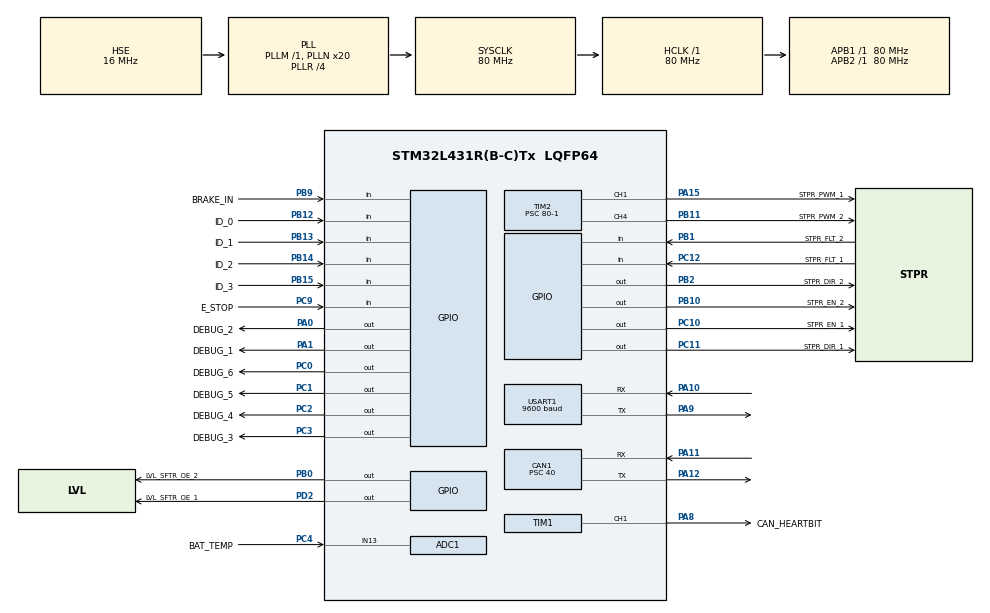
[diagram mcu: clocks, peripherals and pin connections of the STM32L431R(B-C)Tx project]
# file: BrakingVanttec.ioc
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ADC1.Channel-6\#ChannelRegularConversion=ADC_CHANNEL_TEMPSENSOR
ADC1.ContinuousConvMode=ENABLE
ADC1.NbrOfConversionFlag=1
ADC1.OffsetNumber-6\#ChannelRegularConversion=ADC_OFFSET_NONE
ADC1.Rank-6\#ChannelRegularConversion=1
ADC1.SamplingTime-6\#ChannelRegularConversion=ADC_SAMPLETIME_2CYCLES_5
ADC1.master=1
CAN1.BS1=CAN_BS1_13TQ
CAN1.BS2=CAN_BS2_2TQ
CAN1.CalculateBaudRate=125000
CAN1.CalculateTimeBit=8000
CAN1.CalculateTimeQuantum=500.0
CAN1.Prescaler=40
FREERTOS.Tasks01=defaultTask,32,128,default_task,Default,NULL,Dynamic,NULL,NULL
FREERTOS.configGENERATE_RUN_TIME_STATS=1
FREERTOS.configRECORD_STACK_HIGH_ADDRESS=1
FREERTOS.configTIMER_TASK_PRIORITY=6
FREERTOS.configTOTAL_HEAP_SIZE=20000
FREERTOS.configUSE_NEWLIB_REENTRANT=1
FREERTOS.configUSE_STATS_FORMATTING_FUNCTIONS=1
Mcu.Family=STM32L4
Mcu.Name=STM32L431R(B-C)Tx
Mcu.Package=LQFP64
NVIC.PriorityGroup=NVIC_PRIORITYGROUP_4
NVIC.TIM6_DAC_IRQn=true\:15\:0\:false\:false\:true\:false\:false\:true\:true
NVIC.TimeBase=TIM6_DAC_IRQn
NVIC.TimeBaseIP=TIM6
PA0.GPIO_Label=DEBUG_2
PA0.Signal=GPIO_Output
PA1.GPIO_Label=DEBUG_1
PA1.Signal=GPIO_Output
PA10.Mode=Asynchronous
PA10.Signal=USART1_RX
PA11.Mode=CAN_Activate
PA11.Signal=CAN1_RX
PA12.Mode=CAN_Activate
PA12.Signal=CAN1_TX
PA13\ (JTMS-SWDIO).Mode=Trace_Asynchronous_SW
PA13\ (JTMS-SWDIO).Signal=SYS_JTMS-SWDIO
PA14\ (JTCK-SWCLK).Mode=Trace_Asynchronous_SW
PA14\ (JTCK-SWCLK).Signal=SYS_JTCK-SWCLK
PA15\ (JTDI).GPIO_Label=STPR_PWM_1
PA15\ (JTDI).Signal=S_TIM2_CH1
PA8.GPIO_Label=CAN_HEARTBIT
PA8.Signal=S_TIM1_CH1
PA9.Mode=Asynchronous
PA9.Signal=USART1_TX
PB0.GPIO_Label=LVL_SFTR_OE_2
PB0.Signal=GPIO_Output
PB1.GPIO_Label=STPR_FLT_2
PB1.Signal=GPIO_Input
PB10.GPIO_Label=STPR_EN_2
PB10.Signal=GPIO_Output
PB11.GPIO_Label=STPR_PWM_2
PB11.Signal=S_TIM2_CH4
PB12.GPIO_Label=ID_0
PB12.Signal=GPIO_Input
PB13.GPIO_Label=ID_1
PB13.Signal=GPIO_Input
PB14.GPIO_Label=ID_2
PB14.Signal=GPIO_Input
PB15.GPIO_Label=ID_3
PB15.Signal=GPIO_Input
PB2.GPIO_Label=STPR_DIR_2
PB2.Signal=GPIO_Output
PB3\ (JTDO-TRACESWO).Mode=Trace_Asynchronous_SW
PB3\ (JTDO-TRACESWO).Signal=SYS_JTDO-SWO
PB9.GPIO_Label=BRAKE_IN
PB9.Signal=GPIO_Input
PC0.GPIO_Label=DEBUG_6
PC0.Signal=GPIO_Output
PC1.GPIO_Label=DEBUG_5
PC1.Signal=GPIO_Output
PC10.GPIO_Label=STPR_EN_1
PC10.Signal=GPIO_Output
PC11.GPIO_Label=STPR_DIR_1
PC11.Signal=GPIO_Output
PC12.GPIO_Label=STPR_FLT_1
PC12.Signal=GPIO_Input
PC2.GPIO_Label=DEBUG_4
PC2.Signal=GPIO_Output
PC3.GPIO_Label=DEBUG_3
PC3.Signal=GPIO_Output
PC4.GPIO_Label=BAT_TEMP
PC4.Signal=SharedAnalog_PC4
PC9.GPIO_Label=E_STOP
PC9.Signal=GPIO_Input
PD2.GPIO_Label=LVL_SFTR_OE_1
PD2.Signal=GPIO_Output
PH0-OSC_IN\ (PH0).Mode=HSE-External-Oscillator
PH0-OSC_IN\ (PH0).Signal=RCC_OSC_IN
PH1-OSC_OUT\ (PH1).Mode=HSE-External-Oscillator
PH1-OSC_OUT\ (PH1).Signal=RCC_OSC_OUT
ProjectManager.HeapSize=0x200
ProjectManager.StackSize=0x400
ProjectManager.TargetToolchain=STM32CubeIDE
RCC.ADCFreq_Value=80000000
RCC.AHBFreq_Value=80000000
RCC.APB1Freq_Value=80000000
RCC.APB1TimFreq_Value=80000000
RCC.APB2Freq_Value=80000000
RCC.APB2TimFreq_Value=80000000
RCC.CortexFreq_Value=80000000
RCC.HCLKFreq_Value=80000000
RCC.HSE_VALUE=16000000
RCC.HSI48_VALUE=48000000
RCC.HSI_VALUE=16000000
RCC.LSE_VALUE=32768
RCC.MSI_VALUE=4000000
RCC.PLLN=20
RCC.PLLR=RCC_PLLR_DIV4
RCC.PLLSAI1N=20
RCC.PLLSAI1R=RCC_PLLR_DIV4
RCC.PLLSourceVirtual=RCC_PLLSOURCE_HSE
RCC.SYSCLKFreq_VALUE=80000000
RCC.SYSCLKSource=RCC_SYSCLKSOURCE_PLLCLK
RCC.VCOOutputFreq_Value=320000000
SH.S_TIM1_CH1.0=TIM1_CH1,PWM Generation1 CH1
SH.S_TIM2_CH1.0=TIM2_CH1,PWM Generation1 CH1
SH.S_TIM2_CH4.0=TIM2_CH4,PWM Generation4 CH4
SH.SharedAnalog_PC4.0=GPIO_Analog
SH.SharedAnalog_PC4.1=ADC1_IN13,IN13-Single-Ended
TIM1.Channel-PWM\ Generation1\ CH1=TIM_CHANNEL_1
TIM1.Period=100-1
TIM1.Prescaler=80-1
TIM2.Channel-PWM\ Generation1\ CH1=TIM_CHANNEL_1
TIM2.Channel-PWM\ Generation4\ CH4=TIM_CHANNEL_4
TIM2.Period=5000-1 
TIM2.Prescaler=80-1
USART1.BaudRate=9600
USART1.VirtualMode-Asynchronous=VM_ASYNC
VP_ADC1_TempSens_Input.Mode=IN-TempSens
VP_FREERTOS_VS_CMSIS_V2.Mode=CMSIS_V2
VP_SYS_VS_tim6.Mode=TIM6
VP_TIM1_VS_ClockSourceINT.Mode=Internal
VP_TIM2_VS_ClockSourceINT.Mode=Internal
board=custom

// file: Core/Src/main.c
/* USER CODE BEGIN Header */
/**
  ******************************************************************************
  * @file           : main.c
  * @brief          : Main program body
  ******************************************************************************
  * @attention
  *
  * Copyright (c) 2023 STMicroelectronics.
  * All rights reserved.
  *
  * This software is licensed under terms that can be found in the LICENSE file
  * in the root directory of this software component.
  * If no LICENSE file comes with this software, it is provided AS-IS.
  *
  ******************************************************************************
  */
/* USER CODE END Header */
#include "main.h"
#include "cmsis_os.h"

/* USER CODE BEGIN Includes */
#include "stepper_tasks.h"
#include "vanttec_sdv_ids.h"
/* USER CODE END Includes */

ADC_HandleTypeDef hadc1;

CAN_HandleTypeDef hcan1;

TIM_HandleTypeDef htim1;
TIM_HandleTypeDef htim2;

UART_HandleTypeDef huart1;

/* Definitions for defaultTask */
osThreadId_t defaultTaskHandle;
const osThreadAttr_t defaultTask_attributes = {
  .name = "defaultTask",
  .stack_size = 128 * 4,
  .priority = (osPriority_t) osPriorityAboveNormal,
};

void SystemClock_Config(void);
static void MX_GPIO_Init(void);
static void MX_USART1_UART_Init(void);
static void MX_TIM2_Init(void);
static void MX_TIM1_Init(void);
static void MX_ADC1_Init(void);
static void MX_CAN1_Init(void);
void default_task(void *argument);

int main(void)
{

  /* MCU Configuration--------------------------------------------------------*/

  /* Reset of all peripherals, Initializes the Flash interface and the Systick. */
  HAL_Init();

  /* Configure the system clock */
  SystemClock_Config();

  /* Initialize all configured peripherals */
  MX_GPIO_Init();
  MX_USART1_UART_Init();
  MX_TIM2_Init();
  MX_TIM1_Init();
  MX_ADC1_Init();
  MX_CAN1_Init();
  /* USER CODE BEGIN 2 */
  init_canlib(hcan1, VANTTEC_CAN_ID_BRAKING_TX);
  init_canlib_tx();
  init_canlib_rx();
  canlib_init_generic_tasks();
  init_requirements_task();
  init_stepper_tasks();
  /* USER CODE END 2 */

  /* Init scheduler */
  osKernelInitialize();

  /* Create the thread(s) */
  /* creation of defaultTask */
  defaultTaskHandle = osThreadNew(default_task, NULL, &defaultTask_attributes);

  /* Start scheduler */
  osKernelStart();

  /* We should never get here as control is now taken by the scheduler */
  /* Infinite loop */
  while (1)
  {

  }
}

void SystemClock_Config(void)
{
  RCC_OscInitTypeDef RCC_OscInitStruct = {0};
  RCC_ClkInitTypeDef RCC_ClkInitStruct = {0};

  /** Configure the main internal regulator output voltage
  */
  if (HAL_PWREx_ControlVoltageScaling(PWR_REGULATOR_VOLTAGE_SCALE1) != HAL_OK)
  {
    Error_Handler();
  }

  /** Initializes the RCC Oscillators according to the specified parameters
  * in the RCC_OscInitTypeDef structure.
  */
  RCC_OscInitStruct.OscillatorType = RCC_OSCILLATORTYPE_HSE;
  RCC_OscInitStruct.HSEState = RCC_HSE_ON;
  RCC_OscInitStruct.PLL.PLLState = RCC_PLL_ON;
  RCC_OscInitStruct.PLL.PLLSource = RCC_PLLSOURCE_HSE;
  RCC_OscInitStruct.PLL.PLLM = 1;
  RCC_OscInitStruct.PLL.PLLN = 20;
  RCC_OscInitStruct.PLL.PLLP = RCC_PLLP_DIV7;
  RCC_OscInitStruct.PLL.PLLQ = RCC_PLLQ_DIV2;
  RCC_OscInitStruct.PLL.PLLR = RCC_PLLR_DIV4;
  if (HAL_RCC_OscConfig(&RCC_OscInitStruct) != HAL_OK)
  {
    Error_Handler();
  }

  /** Initializes the CPU, AHB and APB buses clocks
  */
  RCC_ClkInitStruct.ClockType = RCC_CLOCKTYPE_HCLK|RCC_CLOCKTYPE_SYSCLK
                              |RCC_CLOCKTYPE_PCLK1|RCC_CLOCKTYPE_PCLK2;
  RCC_ClkInitStruct.SYSCLKSource = RCC_SYSCLKSOURCE_PLLCLK;
  RCC_ClkInitStruct.AHBCLKDivider = RCC_SYSCLK_DIV1;
  RCC_ClkInitStruct.APB1CLKDivider = RCC_HCLK_DIV1;
  RCC_ClkInitStruct.APB2CLKDivider = RCC_HCLK_DIV1;

  if (HAL_RCC_ClockConfig(&RCC_ClkInitStruct, FLASH_LATENCY_4) != HAL_OK)
  {
    Error_Handler();
  }
}

static void MX_ADC1_Init(void)
{

  ADC_ChannelConfTypeDef sConfig = {0};

  /** Common config
  */
  hadc1.Instance = ADC1;
  hadc1.Init.ClockPrescaler = ADC_CLOCK_ASYNC_DIV1;
  hadc1.Init.Resolution = ADC_RESOLUTION_12B;
  hadc1.Init.DataAlign = ADC_DATAALIGN_RIGHT;
  hadc1.Init.ScanConvMode = ADC_SCAN_DISABLE;
  hadc1.Init.EOCSelection = ADC_EOC_SINGLE_CONV;
  hadc1.Init.LowPowerAutoWait = DISABLE;
  hadc1.Init.ContinuousConvMode = ENABLE;
  hadc1.Init.NbrOfConversion = 1;
  hadc1.Init.DiscontinuousConvMode = DISABLE;
  hadc1.Init.ExternalTrigConv = ADC_SOFTWARE_START;
  hadc1.Init.ExternalTrigConvEdge = ADC_EXTERNALTRIGCONVEDGE_NONE;
  hadc1.Init.DMAContinuousRequests = DISABLE;
  hadc1.Init.Overrun = ADC_OVR_DATA_PRESERVED;
  hadc1.Init.OversamplingMode = DISABLE;
  if (HAL_ADC_Init(&hadc1) != HAL_OK)
  {
    Error_Handler();
  }

  /** Configure Regular Channel
  */
  sConfig.Channel = ADC_CHANNEL_TEMPSENSOR;
  sConfig.Rank = ADC_REGULAR_RANK_1;
  sConfig.SamplingTime = ADC_SAMPLETIME_2CYCLES_5;
  sConfig.SingleDiff = ADC_SINGLE_ENDED;
  sConfig.OffsetNumber = ADC_OFFSET_NONE;
  sConfig.Offset = 0;
  if (HAL_ADC_ConfigChannel(&hadc1, &sConfig) != HAL_OK)
  {
    Error_Handler();
  }

}

static void MX_CAN1_Init(void)
{

  hcan1.Instance = CAN1;
  hcan1.Init.Prescaler = 40;
  hcan1.Init.Mode = CAN_MODE_NORMAL;
  hcan1.Init.SyncJumpWidth = CAN_SJW_1TQ;
  hcan1.Init.TimeSeg1 = CAN_BS1_13TQ;
  hcan1.Init.TimeSeg2 = CAN_BS2_2TQ;
  hcan1.Init.TimeTriggeredMode = DISABLE;
  hcan1.Init.AutoBusOff = DISABLE;
  hcan1.Init.AutoWakeUp = DISABLE;
  hcan1.Init.AutoRetransmission = DISABLE;
  hcan1.Init.ReceiveFifoLocked = DISABLE;
  hcan1.Init.TransmitFifoPriority = DISABLE;
  if (HAL_CAN_Init(&hcan1) != HAL_OK)
  {
    Error_Handler();
  }

}

static void MX_TIM1_Init(void)
{

  TIM_ClockConfigTypeDef sClockSourceConfig = {0};
  TIM_MasterConfigTypeDef sMasterConfig = {0};
  TIM_OC_InitTypeDef sConfigOC = {0};
  TIM_BreakDeadTimeConfigTypeDef sBreakDeadTimeConfig = {0};

  htim1.Instance = TIM1;
  htim1.Init.Prescaler = 80-1;
  htim1.Init.CounterMode = TIM_COUNTERMODE_UP;
  htim1.Init.Period = 100-1;
  htim1.Init.ClockDivision = TIM_CLOCKDIVISION_DIV1;
  htim1.Init.RepetitionCounter = 0;
  htim1.Init.AutoReloadPreload = TIM_AUTORELOAD_PRELOAD_DISABLE;
  if (HAL_TIM_Base_Init(&htim1) != HAL_OK)
  {
    Error_Handler();
  }
  sClockSourceConfig.ClockSource = TIM_CLOCKSOURCE_INTERNAL;
  if (HAL_TIM_ConfigClockSource(&htim1, &sClockSourceConfig) != HAL_OK)
  {
    Error_Handler();
  }
  if (HAL_TIM_PWM_Init(&htim1) != HAL_OK)
  {
    Error_Handler();
  }
  sMasterConfig.MasterOutputTrigger = TIM_TRGO_RESET;
  sMasterConfig.MasterOutputTrigger2 = TIM_TRGO2_RESET;
  sMasterConfig.MasterSlaveMode = TIM_MASTERSLAVEMODE_DISABLE;
  if (HAL_TIMEx_MasterConfigSynchronization(&htim1, &sMasterConfig) != HAL_OK)
  {
    Error_Handler();
  }
  sConfigOC.OCMode = TIM_OCMODE_PWM1;
  sConfigOC.Pulse = 0;
  sConfigOC.OCPolarity = TIM_OCPOLARITY_HIGH;
  sConfigOC.OCNPolarity = TIM_OCNPOLARITY_HIGH;
  sConfigOC.OCFastMode = TIM_OCFAST_DISABLE;
  sConfigOC.OCIdleState = TIM_OCIDLESTATE_RESET;
  sConfigOC.OCNIdleState = TIM_OCNIDLESTATE_RESET;
  if (HAL_TIM_PWM_ConfigChannel(&htim1, &sConfigOC, TIM_CHANNEL_1) != HAL_OK)
  {
    Error_Handler();
  }
  sBreakDeadTimeConfig.OffStateRunMode = TIM_OSSR_DISABLE;
  sBreakDeadTimeConfig.OffStateIDLEMode = TIM_OSSI_DISABLE;
  sBreakDeadTimeConfig.LockLevel = TIM_LOCKLEVEL_OFF;
  sBreakDeadTimeConfig.DeadTime = 0;
  sBreakDeadTimeConfig.BreakState = TIM_BREAK_DISABLE;
  sBreakDeadTimeConfig.BreakPolarity = TIM_BREAKPOLARITY_HIGH;
  sBreakDeadTimeConfig.BreakFilter = 0;
  sBreakDeadTimeConfig.Break2State = TIM_BREAK2_DISABLE;
  sBreakDeadTimeConfig.Break2Polarity = TIM_BREAK2POLARITY_HIGH;
  sBreakDeadTimeConfig.Break2Filter = 0;
  sBreakDeadTimeConfig.AutomaticOutput = TIM_AUTOMATICOUTPUT_DISABLE;
  if (HAL_TIMEx_ConfigBreakDeadTime(&htim1, &sBreakDeadTimeConfig) != HAL_OK)
  {
    Error_Handler();
  }
  HAL_TIM_MspPostInit(&htim1);

}

static void MX_TIM2_Init(void)
{

  TIM_ClockConfigTypeDef sClockSourceConfig = {0};
  TIM_MasterConfigTypeDef sMasterConfig = {0};
  TIM_OC_InitTypeDef sConfigOC = {0};

  htim2.Instance = TIM2;
  htim2.Init.Prescaler = 80-1;
  htim2.Init.CounterMode = TIM_COUNTERMODE_UP;
  htim2.Init.Period = 1000-1 ;
  htim2.Init.ClockDivision = TIM_CLOCKDIVISION_DIV1;
  htim2.Init.AutoReloadPreload = TIM_AUTORELOAD_PRELOAD_DISABLE;
  if (HAL_TIM_Base_Init(&htim2) != HAL_OK)
  {
    Error_Handler();
  }
  sClockSourceConfig.ClockSource = TIM_CLOCKSOURCE_INTERNAL;
  if (HAL_TIM_ConfigClockSource(&htim2, &sClockSourceConfig) != HAL_OK)
  {
    Error_Handler();
  }
  if (HAL_TIM_PWM_Init(&htim2) != HAL_OK)
  {
    Error_Handler();
  }
  sMasterConfig.MasterOutputTrigger = TIM_TRGO_RESET;
  sMasterConfig.MasterSlaveMode = TIM_MASTERSLAVEMODE_DISABLE;
  if (HAL_TIMEx_MasterConfigSynchronization(&htim2, &sMasterConfig) != HAL_OK)
  {
    Error_Handler();
  }
  sConfigOC.OCMode = TIM_OCMODE_PWM1;
  sConfigOC.Pulse = 0;
  sConfigOC.OCPolarity = TIM_OCPOLARITY_HIGH;
  sConfigOC.OCFastMode = TIM_OCFAST_DISABLE;
  if (HAL_TIM_PWM_ConfigChannel(&htim2, &sConfigOC, TIM_CHANNEL_1) != HAL_OK)
  {
    Error_Handler();
  }
  if (HAL_TIM_PWM_ConfigChannel(&htim2, &sConfigOC, TIM_CHANNEL_4) != HAL_OK)
  {
    Error_Handler();
  }
  HAL_TIM_MspPostInit(&htim2);

}

static void MX_USART1_UART_Init(void)
{

  huart1.Instance = USART1;
  huart1.Init.BaudRate = 9600;
  huart1.Init.WordLength = UART_WORDLENGTH_8B;
  huart1.Init.StopBits = UART_STOPBITS_1;
  huart1.Init.Parity = UART_PARITY_NONE;
  huart1.Init.Mode = UART_MODE_TX_RX;
  huart1.Init.HwFlowCtl = UART_HWCONTROL_NONE;
  huart1.Init.OverSampling = UART_OVERSAMPLING_16;
  huart1.Init.OneBitSampling = UART_ONE_BIT_SAMPLE_DISABLE;
  huart1.AdvancedInit.AdvFeatureInit = UART_ADVFEATURE_NO_INIT;
  if (HAL_UART_Init(&huart1) != HAL_OK)
  {
    Error_Handler();
  }

}

static void MX_GPIO_Init(void)
{
  GPIO_InitTypeDef GPIO_InitStruct = {0};

  /* GPIO Ports Clock Enable */
  __HAL_RCC_GPIOH_CLK_ENABLE();
  __HAL_RCC_GPIOC_CLK_ENABLE();
  __HAL_RCC_GPIOA_CLK_ENABLE();
  __HAL_RCC_GPIOB_CLK_ENABLE();
  __HAL_RCC_GPIOD_CLK_ENABLE();

  /*Configure GPIO pin Output Level */
  HAL_GPIO_WritePin(GPIOC, DEBUG_6_Pin|DEBUG_5_Pin|DEBUG_4_Pin|DEBUG_3_Pin
                          |STPR_EN_1_Pin|STPR_DIR_1_Pin, GPIO_PIN_RESET);

  /*Configure GPIO pin Output Level */
  HAL_GPIO_WritePin(GPIOA, DEBUG_2_Pin|DEBUG_1_Pin, GPIO_PIN_RESET);

  /*Configure GPIO pin Output Level */
  HAL_GPIO_WritePin(GPIOB, LVL_SFTR_OE_2_Pin|STPR_DIR_2_Pin|STPR_EN_2_Pin, GPIO_PIN_RESET);

  /*Configure GPIO pin Output Level */
  HAL_GPIO_WritePin(LVL_SFTR_OE_1_GPIO_Port, LVL_SFTR_OE_1_Pin, GPIO_PIN_RESET);

  /*Configure GPIO pins : DEBUG_6_Pin DEBUG_5_Pin DEBUG_4_Pin DEBUG_3_Pin
                           STPR_EN_1_Pin STPR_DIR_1_Pin */
  GPIO_InitStruct.Pin = DEBUG_6_Pin|DEBUG_5_Pin|DEBUG_4_Pin|DEBUG_3_Pin
                          |STPR_EN_1_Pin|STPR_DIR_1_Pin;
  GPIO_InitStruct.Mode = GPIO_MODE_OUTPUT_PP;
  GPIO_InitStruct.Pull = GPIO_NOPULL;
  GPIO_InitStruct.Speed = GPIO_SPEED_FREQ_LOW;
  HAL_GPIO_Init(GPIOC, &GPIO_InitStruct);

  /*Configure GPIO pins : DEBUG_2_Pin DEBUG_1_Pin */
  GPIO_InitStruct.Pin = DEBUG_2_Pin|DEBUG_1_Pin;
  GPIO_InitStruct.Mode = GPIO_MODE_OUTPUT_PP;
  GPIO_InitStruct.Pull = GPIO_NOPULL;
  GPIO_InitStruct.Speed = GPIO_SPEED_FREQ_LOW;
  HAL_GPIO_Init(GPIOA, &GPIO_InitStruct);

  /*Configure GPIO pins : LVL_SFTR_OE_2_Pin STPR_DIR_2_Pin STPR_EN_2_Pin */
  GPIO_InitStruct.Pin = LVL_SFTR_OE_2_Pin|STPR_DIR_2_Pin|STPR_EN_2_Pin;
  GPIO_InitStruct.Mode = GPIO_MODE_OUTPUT_PP;
  GPIO_InitStruct.Pull = GPIO_NOPULL;
  GPIO_InitStruct.Speed = GPIO_SPEED_FREQ_LOW;
  HAL_GPIO_Init(GPIOB, &GPIO_InitStruct);

  /*Configure GPIO pins : STPR_FLT_2_Pin ID_0_Pin ID_1_Pin ID_2_Pin
                           ID_3_Pin BRAKE_IN_Pin */
  GPIO_InitStruct.Pin = STPR_FLT_2_Pin|ID_0_Pin|ID_1_Pin|ID_2_Pin
                          |ID_3_Pin|BRAKE_IN_Pin;
  GPIO_InitStruct.Mode = GPIO_MODE_INPUT;
  GPIO_InitStruct.Pull = GPIO_NOPULL;
  HAL_GPIO_Init(GPIOB, &GPIO_InitStruct);

  /*Configure GPIO pins : E_STOP_Pin STPR_FLT_1_Pin */
  GPIO_InitStruct.Pin = E_STOP_Pin|STPR_FLT_1_Pin;
  GPIO_InitStruct.Mode = GPIO_MODE_INPUT;
  GPIO_InitStruct.Pull = GPIO_NOPULL;
  HAL_GPIO_Init(GPIOC, &GPIO_InitStruct);

  /*Configure GPIO pin : LVL_SFTR_OE_1_Pin */
  GPIO_InitStruct.Pin = LVL_SFTR_OE_1_Pin;
  GPIO_InitStruct.Mode = GPIO_MODE_OUTPUT_PP;
  GPIO_InitStruct.Pull = GPIO_NOPULL;
  GPIO_InitStruct.Speed = GPIO_SPEED_FREQ_LOW;
  HAL_GPIO_Init(LVL_SFTR_OE_1_GPIO_Port, &GPIO_InitStruct);

}

void default_task(void *argument)
{
  for(;;)
  {
    osDelay(1);
  }
}

void HAL_TIM_PeriodElapsedCallback(TIM_HandleTypeDef *htim)
{
  if (htim->Instance == TIM6) {
    HAL_IncTick();
  }
}

void Error_Handler(void)
{
  __disable_irq();
  while (1)
  {
  }
}
